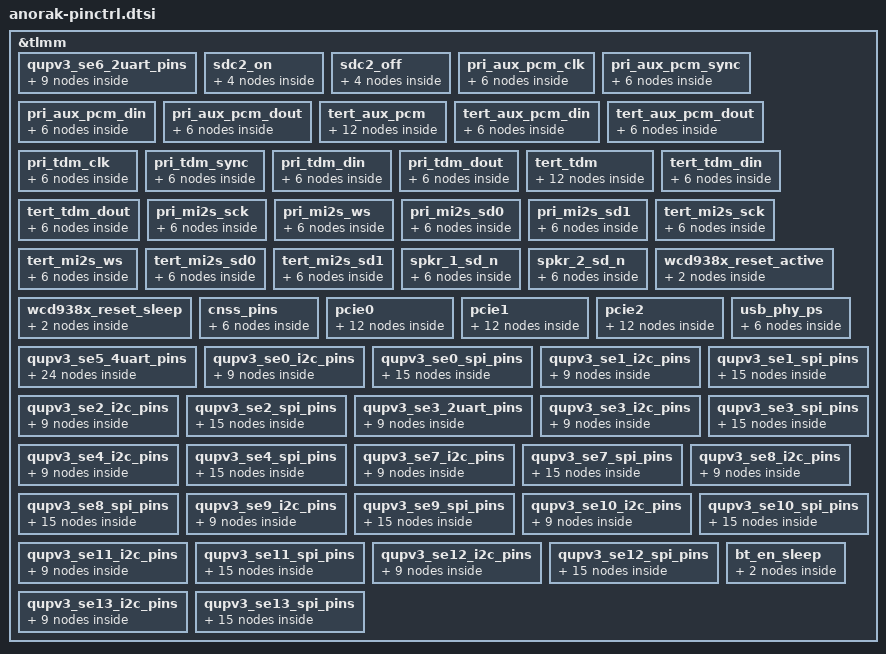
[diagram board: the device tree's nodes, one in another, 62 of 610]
&tlmm {

	qupv3_se6_2uart_pins: qupv3_se6_2uart_pins {
		qupv3_se6_2uart_tx_active: qupv3_se6_2uart_tx_active {
			mux {
				pins = "gpio156";
				function = "qup0_se6_l2";
			};

			config {
				pins = "gpio156";
				drive-strength = <2>;
				bias-disable;
			};
		};

		qupv3_se6_2uart_rx_active: qupv3_se6_2uart_rx_active {
			mux {
				pins = "gpio157";
				function = "qup0_se6_l3";
			};

			config {
				pins = "gpio157";
				drive-strength = <2>;
				bias-disable;
			};
		};

		qupv3_se6_2uart_sleep: qupv3_se6_2uart_sleep {
			mux {
				pins = "gpio156", "gpio157";
				function = "gpio";
			};

			config {
				pins = "gpio156", "gpio157";
				drive-strength = <2>;
				bias-pull-down;
			};
		};
	};

	sdc2_on: sdc2_on {
		clk {
			pins = "sdc2_clk";
			bias-disable;
			drive-strength = <16>;
		};

		cmd {
			pins = "sdc2_cmd";
			bias-pull-up;
			drive-strength = <10>;
		};

		data {
			pins = "sdc2_data";
			bias-pull-up;
			drive-strength = <10>;
		};

		sd-cd {
			pins = "gpio175";
			bias-pull-up;
			drive-strength = <2>;
		};
	};

	sdc2_off: sdc2_off {
		clk {
			pins = "sdc2_clk";
			bias-disable;
			drive-strength = <2>;
		};

		cmd {
			pins = "sdc2_cmd";
			bias-pull-up;
			drive-strength = <2>;
		};

		data {
			pins = "sdc2_data";
			bias-pull-up;
			drive-strength = <2>;
		};

		sd-cd {
			pins = "gpio175";
			bias-pull-up;
			drive-strength = <2>;
		};
	};

	pri_aux_pcm_clk {
		pri_aux_pcm_clk_sleep: pri_aux_pcm_clk_sleep {
			mux {
				pins = "gpio164";
				function = "gpio";
			};

			config {
				pins = "gpio164";
				drive-strength = <2>;   /* 2 mA */
				bias-pull-down;         /* PULL DOWN */
				input-enable;
			};
		};

		pri_aux_pcm_clk_active: pri_aux_pcm_clk_active {
			mux {
				pins = "gpio164";
				function = "i2s0_sck";
			};

			config {
				pins = "gpio164";
				drive-strength = <8>;   /* 8 mA */
				bias-disable;           /* NO PULL */
				output-high;
			};
		};
	};

	pri_aux_pcm_sync {
		pri_aux_pcm_sync_sleep: pri_aux_pcm_sync_sleep {
			mux {
				pins = "gpio166";
				function = "gpio";
			};

			config {
				pins = "gpio166";
				drive-strength = <2>;   /* 2 mA */
				bias-pull-down;         /* PULL DOWN */
				input-enable;
			};
		};

		pri_aux_pcm_sync_active: pri_aux_pcm_sync_active {
			mux {
				pins = "gpio166";
				function = "i2s0_ws";
			};

			config {
				pins = "gpio166";
				drive-strength = <8>;   /* 8 mA */
				bias-disable;           /* NO PULL */
				output-high;
			};
		};
	};

	pri_aux_pcm_din {
		pri_aux_pcm_din_sleep: pri_aux_pcm_din_sleep {
			mux {
				pins = "gpio163";
				function = "gpio";
			};

			config {
				pins = "gpio163";
				drive-strength = <2>;   /* 2 mA */
				bias-pull-down;         /* PULL DOWN */
				input-enable;
			};
		};

		pri_aux_pcm_din_active: pri_aux_pcm_din_active {
			mux {
				pins = "gpio163";
				function = "i2s0_data0";
			};

			config {
				pins = "gpio163";
				drive-strength = <8>;   /* 8 mA */
				bias-disable;           /* NO PULL */
			};
		};
	};

	pri_aux_pcm_dout {
		pri_aux_pcm_dout_sleep: pri_aux_pcm_dout_sleep {
			mux {
				pins = "gpio165";
				function = "gpio";
			};

			config {
				pins = "gpio165";
				drive-strength = <2>;   /* 2 mA */
				bias-pull-down;         /* PULL DOWN */
				input-enable;
			};
		};

		pri_aux_pcm_dout_active: pri_aux_pcm_dout_active {
			mux {
				pins = "gpio165";
				function = "i2s0_data1";
			};

			config {
				pins = "gpio165";
				drive-strength = <8>;   /* 8 mA */
				bias-disable;           /* NO PULL */
			};
		};
	};

	tert_aux_pcm {
		tert_aux_pcm_clk_sleep: tert_aux_pcm_clk_sleep {
			mux {
				pins = "gpio156";
				function = "gpio";
			};

			config {
				pins = "gpio156";
				drive-strength = <2>;   /* 2 mA */
				bias-pull-down;         /* PULL DOWN */
				input-enable;
			};
		};

		tert_aux_pcm_clk_active: tert_aux_pcm_clk_active {
			mux {
				pins = "gpio156";
				function = "i2s2_sck";
			};

			config {
				pins = "gpio156";
				drive-strength = <8>;   /* 8 mA */
				bias-disable;           /* NO PULL */
				output-high;
			};
		};

		tert_aux_pcm_ws_sleep: tert_aux_pcm_ws_sleep {
			mux {
				pins = "gpio157";
				function = "gpio";
			};

			config {
				pins = "gpio157";
				drive-strength = <2>;   /* 2 mA */
				bias-pull-down;         /* PULL DOWN */
				input-enable;
			};
		};

		tert_aux_pcm_ws_active: tert_aux_pcm_ws_active {
			mux {
				pins = "gpio157";
				function = "i2s2_ws";
			};

			config {
				pins = "gpio157";
				drive-strength = <8>;   /* 8 mA */
				bias-disable;           /* NO PULL */
				output-high;
			};
		};
	};

	tert_aux_pcm_din {
		tert_aux_pcm_din_sleep: tert_aux_pcm_din_sleep {
			mux {
				pins = "gpio155";
				function = "gpio";
			};

			config {
				pins = "gpio155";
				drive-strength = <2>;   /* 2 mA */
				bias-pull-down;         /* PULL DOWN */
				input-enable;
			};
		};

		tert_aux_pcm_din_active: tert_aux_pcm_din_active {
			mux {
				pins = "gpio155";
				function = "i2s2_data0";
			};

			config {
				pins = "gpio155";
				drive-strength = <8>;   /* 8 mA */
				bias-disable;           /* NO PULL */
			};
		};
	};

	tert_aux_pcm_dout {
		tert_aux_pcm_dout_sleep: tert_aux_pcm_dout_sleep {
			mux {
				pins = "gpio154";
				function = "gpio";
			};

			config {
				pins = "gpio154";
				drive-strength = <2>;   /* 2 mA */
				bias-pull-down;         /* PULL DOWN */
				input-enable;
			};
		};

		tert_aux_pcm_dout_active: tert_aux_pcm_dout_active {
			mux {
				pins = "gpio154";
				function = "i2s2_data1";
			};

			config {
				pins = "gpio154";
				drive-strength = <8>;   /* 8 mA */
				bias-disable;           /* NO PULL */
			};
		};
	};

	pri_tdm_clk {
		pri_tdm_clk_sleep: pri_tdm_clk_sleep {
			mux {
				pins = "gpio164";
				function = "gpio";
			};

			config {
				pins = "gpio164";
				drive-strength = <2>;   /* 2 mA */
				bias-pull-down;         /* PULL DOWN */
				input-enable;
			};
		};

		pri_tdm_clk_active: pri_tdm_clk_active {
			mux {
				pins = "gpio164";
				function = "i2s0_sck";
			};

			config {
				pins = "gpio164";
				drive-strength = <8>;   /* 8 mA */
				bias-disable;           /* NO PULL */
				output-high;
			};
		};
	};

	pri_tdm_sync {
		pri_tdm_sync_sleep: pri_tdm_sync_sleep {
			mux {
				pins = "gpio166";
				function = "gpio";
			};

			config {
				pins = "gpio166";
				drive-strength = <2>;   /* 2 mA */
				bias-pull-down;         /* PULL DOWN */
				input-enable;
			};
		};

		pri_tdm_sync_active: pri_tdm_sync_active {
			mux {
				pins = "gpio166";
				function = "i2s0_ws";
			};

			config {
				pins = "gpio166";
				drive-strength = <8>;   /* 8 mA */
				bias-disable;           /* NO PULL */
				output-high;
			};
		};
	};

	pri_tdm_din {
		pri_tdm_din_sleep: pri_tdm_din_sleep {
			mux {
				pins = "gpio163";
				function = "gpio";
			};

			config {
				pins = "gpio163";
				drive-strength = <2>;   /* 2 mA */
				bias-pull-down;         /* PULL DOWN */
				input-enable;
			};
		};

		pri_tdm_din_active: pri_tdm_din_active {
			mux {
				pins = "gpio163";
				function = "i2s0_data0";
			};

			config {
				pins = "gpio163";
				drive-strength = <8>;   /* 8 mA */
				bias-disable;           /* NO PULL */
			};
		};
	};

	pri_tdm_dout {
		pri_tdm_dout_sleep: pri_tdm_dout_sleep {
			mux {
				pins = "gpio165";
				function = "gpio";
			};

			config {
				pins = "gpio165";
				drive-strength = <2>;   /* 2 mA */
				bias-pull-down;         /* PULL DOWN */
				input-enable;
			};
		};

		pri_tdm_dout_active: pri_tdm_dout_active {
			mux {
				pins = "gpio165";
				function = "i2s0_data1";
			};

			config {
				pins = "gpio165";
				drive-strength = <8>;   /* 8 mA */
				bias-disable;           /* NO PULL */
			};
		};
	};

	tert_tdm {
		tert_tdm_clk_sleep: tert_tdm_clk_sleep {
			mux {
				pins = "gpio156";
				function = "gpio";
			};

			config {
				pins = "gpio156";
				drive-strength = <2>;   /* 2 mA */
				bias-pull-down;         /* PULL DOWN */
				input-enable;
			};
		};

		tert_tdm_clk_active: tert_tdm_clk_active {
			mux {
				pins = "gpio156";
				function = "i2s2_sck";
			};

			config {
				pins = "gpio156";
				drive-strength = <8>;   /* 8 mA */
				bias-disable;           /* NO PULL */
				output-high;
			};
		};

		tert_tdm_ws_sleep: tert_tdm_ws_sleep {
			mux {
				pins = "gpio157";
				function = "gpio";
			};

			config {
				pins = "gpio157";
				drive-strength = <2>;   /* 2 mA */
				bias-pull-down;         /* PULL DOWN */
				input-enable;
			};
		};

		tert_tdm_ws_active: tert_tdm_ws_active {
			mux {
				pins = "gpio157";
				function = "i2s2_ws";
			};

			config {
				pins = "gpio157";
				drive-strength = <8>;   /* 8 mA */
				bias-disable;           /* NO PULL */
				output-high;
			};
		};
	};

	tert_tdm_din {
		tert_tdm_din_sleep: tert_tdm_din_sleep {
			mux {
				pins = "gpio155";
				function = "gpio";
			};

			config {
				pins = "gpio155";
				drive-strength = <2>;   /* 2 mA */
				bias-pull-down;         /* PULL DOWN */
				input-enable;
			};
		};

		tert_tdm_din_active: tert_tdm_din_active {
			mux {
				pins = "gpio155";
				function = "i2s2_data0";
			};

			config {
				pins = "gpio155";
				drive-strength = <8>;   /* 8 mA */
				bias-disable;           /* NO PULL */
			};
		};
	};

	tert_tdm_dout {
		tert_tdm_dout_sleep: tert_tdm_dout_sleep {
			mux {
				pins = "gpio154";
				function = "gpio";
			};

			config {
				pins = "gpio154";
				drive-strength = <2>;   /* 2 mA */
				bias-pull-down;         /* PULL DOWN */
				input-enable;
			};
		};

		tert_tdm_dout_active: tert_tdm_dout_active {
			mux {
				pins = "gpio154";
				function = "i2s2_data1";
			};

			config {
				pins = "gpio154";
				drive-strength = <8>;   /* 8 mA */
				bias-disable;           /* NO PULL */
			};
		};
	};

	pri_mi2s_sck {
		pri_mi2s_sck_sleep: pri_mi2s_sck_sleep {
			mux {
				pins = "gpio164";
				function = "gpio";
			};

			config {
				pins = "gpio164";
				drive-strength = <2>;   /* 2 mA */
				bias-pull-down;         /* PULL DOWN */
				input-enable;
			};
		};

		pri_mi2s_sck_active: pri_mi2s_sck_active {
			mux {
				pins = "gpio164";
				function = "i2s0_sck";
			};

			config {
				pins = "gpio164";
				drive-strength = <8>;   /* 8 mA */
				bias-disable;           /* NO PULL */
				output-high;
			};
		};
	};

	pri_mi2s_ws {
		pri_mi2s_ws_sleep: pri_mi2s_ws_sleep {
			mux {
				pins = "gpio166";
				function = "gpio";
			};

			config {
				pins = "gpio166";
				drive-strength = <2>;   /* 2 mA */
				bias-pull-down;         /* PULL DOWN */
				input-enable;
			};
		};

		pri_mi2s_ws_active: pri_mi2s_ws_active {
			mux {
				pins = "gpio166";
				function = "i2s0_ws";
			};

			config {
				pins = "gpio166";
				drive-strength = <8>;   /* 8 mA */
				bias-disable;           /* NO PULL */
				output-high;
			};
		};
	};

	pri_mi2s_sd0 {
		pri_mi2s_sd0_sleep: pri_mi2s_sd0_sleep {
			mux {
				pins = "gpio163";
				function = "gpio";
			};

			config {
				pins = "gpio163";
				drive-strength = <2>;   /* 2 mA */
				bias-pull-down;         /* PULL DOWN */
				input-enable;
			};
		};

		pri_mi2s_sd0_active: pri_mi2s_sd0_active {
			mux {
				pins = "gpio163";
				function = "i2s0_data0";
			};

			config {
				pins = "gpio163";
				drive-strength = <8>;   /* 8 mA */
				bias-disable;           /* NO PULL */
				output-high;
			};
		};
	};

	pri_mi2s_sd1 {
		pri_mi2s_sd1_sleep: pri_mi2s_sd1_sleep {
			mux {
				pins = "gpio165";
				function = "gpio";
			};

			config {
				pins = "gpio165";
				drive-strength = <2>;   /* 2 mA */
				bias-pull-down;         /* PULL DOWN */
				input-enable;
			};
		};

		pri_mi2s_sd1_active: pri_mi2s_sd1_active {
			mux {
				pins = "gpio165";
				function = "i2s0_data1";
			};

			config {
				pins = "gpio165";
				drive-strength = <8>;   /* 8 mA */
				bias-disable;           /* NO PULL */
				output-high;
			};
		};
	};

	tert_mi2s_sck {
		tert_mi2s_sck_sleep: tert_mi2s_sck_sleep {
			mux {
				pins = "gpio156";
				function = "gpio";
			};

			config {
				pins = "gpio156";
				drive-strength = <2>;   /* 2 mA */
				bias-pull-down;         /* PULL DOWN */
				input-enable;
			};
		};

		tert_mi2s_sck_active: tert_mi2s_sck_active {
			mux {
				pins = "gpio156";
				function = "i2s2_sck";
			};

			config {
				pins = "gpio156";
				drive-strength = <8>;   /* 8 mA */
				bias-disable;           /* NO PULL */
			};
		};
	};

	tert_mi2s_ws {
		tert_mi2s_ws_sleep: tert_mi2s_ws_sleep {
			mux {
				pins = "gpio157";
				function = "gpio";
			};

			config {
				pins = "gpio157";
				drive-strength = <2>;   /* 2 mA */
				bias-pull-down;         /* PULL DOWN */
				input-enable;
			};
		};

		tert_mi2s_ws_active: tert_mi2s_ws_active {
			mux {
				pins = "gpio157";
				function = "i2s2_ws";
			};

			config {
				pins = "gpio157";
				drive-strength = <8>;   /* 8 mA */
				bias-disable;           /* NO PULL */
			};
		};
	};

	tert_mi2s_sd0 {
		tert_mi2s_sd0_sleep: tert_mi2s_sd0_sleep {
			mux {
				pins = "gpio155";
				function = "gpio";
			};

			config {
				pins = "gpio155";
				drive-strength = <2>;   /* 2 mA */
				bias-pull-down;         /* PULL DOWN */
				input-enable;
			};
		};

		tert_mi2s_sd0_active: tert_mi2s_sd0_active {
			mux {
				pins = "gpio155";
				function = "i2s2_data0";
			};

			config {
				pins = "gpio155";
				drive-strength = <8>;   /* 8 mA */
				bias-disable;           /* NO PULL */
			};
		};
	};

	tert_mi2s_sd1 {
		tert_mi2s_sd1_sleep: tert_mi2s_sd1_sleep {
			mux {
				pins = "gpio154";
				function = "gpio";
			};

			config {
				pins = "gpio154";
				drive-strength = <2>;   /* 2 mA */
				bias-pull-down;         /* PULL DOWN */
				input-enable;
			};
		};

		tert_mi2s_sd1_active: tert_mi2s_sd1_active {
			mux {
				pins = "gpio154";
				function = "i2s2_data1";
			};

			config {
				pins = "gpio154";
				drive-strength = <8>;   /* 8 mA */
				bias-disable;           /* NO PULL */
			};
		};
	};

	/* WSA speaker reset pins */
	spkr_1_sd_n {
		spkr_1_sd_n_sleep: spkr_1_sd_n_sleep {
			mux {
				pins = "gpio176";
				function = "gpio";
			};

			config {
				pins = "gpio176";
				drive-strength = <2>;   /* 2 mA */
				bias-pull-down;
				input-enable;
			};
		};

		spkr_1_sd_n_active: spkr_1_sd_n_active {
			mux {
				pins = "gpio176";
				function = "gpio";
			};

			config {
				pins = "gpio176";
				drive-strength = <16>;   /* 16 mA */
				bias-disable;
				output-high;
			};
		};
	};

	spkr_2_sd_n {
		spkr_2_sd_n_sleep: spkr_2_sd_n_sleep {
			mux {
				pins = "gpio177";
				function = "gpio";
			};

			config {
			pins = "gpio177";
			drive-strength = <2>;   /* 2 mA */
			bias-pull-down;
			input-enable;
			};
		};

		spkr_2_sd_n_active: spkr_2_sd_n_active {
			mux {
				pins = "gpio177";
				function = "gpio";
			};

			config {
				pins = "gpio177";
				drive-strength = <16>;   /* 16 mA */
				bias-disable;
				output-high;
			};
		};
	};

	/* WCD reset pin */
	wcd938x_reset_active: wcd938x_reset_active {
		mux {
			pins = "gpio180";
			function = "gpio";
		};

		config {
			pins = "gpio180";
			drive-strength = <16>;
			output-high;
		};
	};

	wcd938x_reset_sleep: wcd938x_reset_sleep {
		mux {
			pins = "gpio180";
			function = "gpio";
		};

		config {
			pins = "gpio180";
			drive-strength = <16>;
			bias-disable;
			output-low;
		};
	};
	cnss_pins: cnss_pins {
		cnss_wlan_en_active: cnss_wlan_en_active {
			mux {
				pins = "gpio120";
				function = "gpio";
			};

			config {
				pins = "gpio120";
				drive-strength = <16>;
				output-high;
				bias-pull-up;
			};
		};

		cnss_wlan_en_sleep: cnss_wlan_en_sleep {
			mux {
				pins = "gpio120";
				function = "gpio";
			};

			config {
				pins = "gpio120";
				drive-strength = <2>;
				output-low;
				bias-pull-down;
			};
		};
	};


	pcie0 {
		pcie0_perst_default: pcie0_perst_default {
			mux {
				pins = "gpio117";
				function = "gpio";
			};

			config {
				pins = "gpio117";
				drive-strength = <2>;
				bias-pull-down;
			};
		};

		pcie0_clkreq_default: pcie0_clkreq_default {
			mux {
				pins = "gpio118";
				function = "pcie0_clk_req";
			};

			config {
				pins = "gpio118";
				drive-strength = <2>;
				bias-pull-up;
			};
		};

		pcie0_wake_default: pcie0_wake_default {
			mux {
				pins = "gpio119";
				function = "gpio";
			};

			config {
				pins = "gpio119";
				drive-strength = <2>;
				bias-pull-up;
			};
		};

		pcie0_clkreq_sleep: pcie0_clkreq_sleep {
			mux {
				pins = "gpio118";
				function = "gpio";
			};

			config {
				pins = "gpio118";
				drive-strength = <2>;
				bias-pull-up;
			};
		};
	};

	pcie1 {
		pcie1_perst_default: pcie1_perst_default {
			mux {
				pins = "gpio141";
				function = "gpio";
			};

			config {
				pins = "gpio141";
				drive-strength = <2>;
				bias-pull-down;
			};
		};

		pcie1_clkreq_default: pcie1_clkreq_default {
			mux {
				pins = "gpio142";
				function = "pcie1_clk_req";
			};

			config {
				pins = "gpio142";
				drive-strength = <2>;
				bias-pull-up;
			};
		};

		pcie1_wake_default: pcie1_wake_default {
			mux {
				pins = "gpio143";
				function = "gpio";
			};

			config {
				pins = "gpio143";
				drive-strength = <2>;
				bias-pull-up;
			};
		};

		pcie1_clkreq_sleep: pcie1_clkreq_sleep {
			mux {
				pins = "gpio142";
				function = "gpio";
			};

			config {
				pins = "gpio142";
				drive-strength = <2>;
				bias-pull-up;
			};
		};
	};

	pcie2 {
		pcie2_perst_default: pcie2_perst_default {
			mux {
				pins = "gpio170";
				function = "gpio";
			};

			config {
				pins = "gpio170";
				drive-strength = <16>;
				bias-pull-down;
			};
		};

		pcie2_clkreq_default: pcie2_clkreq_default {
			mux {
				pins = "gpio171";
				function = "pcie2_clk_req";
			};

			config {
				pins = "gpio171";
				drive-strength = <2>;
				bias-pull-up;
			};
		};

		pcie2_wake_default: pcie2_wake_default {
			mux {
				pins = "gpio172";
				function = "gpio";
			};

			config {
				pins = "gpio172";
				drive-strength = <2>;
				bias-pull-up;
			};
		};

		pcie2_clkreq_sleep: pcie2_clkreq_sleep {
			mux {
				pins = "gpio171";
				function = "gpio";
			};

			config {
				pins = "gpio171";
				drive-strength = <2>;
				bias-pull-up;
			};
		};
	};

	usb_phy_ps: usb_phy_ps {
		usb3phy_portselect_default: usb3phy_portselect_default {
			mux {
				pins = "gpio160";
				function = "usb0_phy_ps";
			};

			config {
				pins = "gpio160";
				bias-disable;
				drive-strength = <2>;
			};
		};

		usb3phy_portselect_gpio: usb3phy_portselect_gpio {
			mux {
				pins = "gpio160";
				function = "gpio";
			};

			config {
				pins = "gpio160";
				drive-strength = <2>;
				bias-disable;
				input-enable;
			};
		};
	};

	qupv3_se5_4uart_pins: qupv3_se5_4uart_pins {
		qupv3_se5_default_cts: qupv3_se5_default_cts {
			mux {
				pins = "gpio126";
				function = "gpio";
			};

			config {
				pins = "gpio126";
				drive-strength = <2>;
				bias-disable;
			};
		};

		qupv3_se5_default_rts: qupv3_se5_default_rts {
			mux {
				pins = "gpio127";
				function = "gpio";
			};

			config {
				pins = "gpio127";
				drive-strength = <2>;
				bias-pull-down;
			};
		};

		qupv3_se5_default_tx: qupv3_se5_default_tx {
			mux {
				pins = "gpio128";
				function = "gpio";
			};

			config {
				pins = "gpio128";
				drive-strength = <2>;
				bias-pull-up;
			};
		};

		qupv3_se5_default_rx: qupv3_se5_default_rx {
			mux {
				pins = "gpio129";
				function = "gpio";
			};

			config {
				pins = "gpio129";
				drive-strength = <2>;
				bias-pull-down;
			};
		};

		qupv3_se5_cts: qupv3_se5_cts {
			mux {
				pins = "gpio126";
				function = "qup0_se5_l0";
			};

			config {
				pins = "gpio126";
				drive-strength = <2>;
				bias-disable;
			};
		};

		qupv3_se5_rts: qupv3_se5_rts {
			mux {
				pins = "gpio127";
				function = "qup0_se5_l1";
			};

			config {
				pins = "gpio127";
				drive-strength = <2>;
				bias-pull-down;
			};
		};

		qupv3_se5_tx: qupv3_se5_tx {
			mux {
				pins = "gpio128";
				function = "qup0_se5_l2";
			};

			config {
				pins = "gpio128";
				drive-strength = <2>;
				bias-pull-up;
			};
		};

		qupv3_se5_rx: qupv3_se5_rx {
			mux {
				pins = "gpio129";
				function = "qup0_se5_l3";
			};

			config {
				pins = "gpio129";
				drive-strength = <2>;
				bias-disable;
			};
		};
	};

	qupv3_se0_i2c_pins: qupv3_se0_i2c_pins {
		qupv3_se0_i2c_sda_active: qupv3_se0_i2c_sda_active {
			mux {
				pins = "gpio94";
				function = "qup0_se0_l0";
			};

			config {
				pins = "gpio94";
				drive-strength = <2>;
				bias-pull-up;
			};
		};

		qupv3_se0_i2c_scl_active: qupv3_se0_i2c_scl_active {
			mux {
				pins = "gpio95";
				function = "qup0_se0_l1";
			};

			config {
				pins = "gpio95";
				drive-strength = <2>;
				bias-pull-up;
			};
		};

		qupv3_se0_i2c_sleep: qupv3_se0_i2c_sleep {
			mux {
				pins = "gpio94", "gpio95";
				function = "gpio";
			};

			config {
				pins = "gpio94", "gpio95";
				drive-strength = <2>;
				bias-disable;
			};
		};
	};

	qupv3_se0_spi_pins: qupv3_se0_spi_pins {
		qupv3_se0_spi_miso_active: qupv3_se0_spi_miso_active {
			mux {
				pins = "gpio94";
				function = "qup0_se0_l0";
			};

			config {
				pins = "gpio94";
				drive-strength = <6>;
				bias-disable;
			};
		};

		qupv3_se0_spi_mosi_active: qupv3_se0_spi_mosi_active {
			mux {
				pins = "gpio95";
				function = "qup0_se0_l1";
			};

			config {
				pins = "gpio95";
				drive-strength = <6>;
				bias-disable;
			};
		};

		qupv3_se0_spi_clk_active: qupv3_se0_spi_clk_active {
			mux {
				pins = "gpio96";
				function = "qup0_se0_l2";
			};

			config {
				pins = "gpio96";
				drive-strength = <6>;
				bias-disable;
			};
		};

		qupv3_se0_spi_cs_active: qupv3_se0_spi_cs_active {
			mux {
				pins = "gpio97";
				function = "qup0_se0_l3";
			};

			config {
				pins = "gpio97";
				drive-strength = <6>;
				bias-disable;
			};
		};

		qupv3_se0_spi_sleep: qupv3_se0_spi_sleep {
			mux {
				pins = "gpio94", "gpio95",
					"gpio96", "gpio97";
				function = "gpio";
			};

			config {
				pins = "gpio94", "gpio95",
					"gpio96", "gpio97";
				drive-strength = <6>;
				bias-disable;
			};
		};
	};

	qupv3_se1_i2c_pins: qupv3_se1_i2c_pins {
		qupv3_se1_i2c_sda_active: qupv3_se1_i2c_sda_active {
			mux {
				pins = "gpio98";
				function = "qup0_se1_l0";
			};

			config {
				pins = "gpio98";
				drive-strength = <2>;
				bias-pull-up;
			};
		};

		qupv3_se1_i2c_scl_active: qupv3_se1_i2c_scl_active {
			mux {
				pins = "gpio99";
				function = "qup0_se1_l1";
			};

			config {
				pins = "gpio99";
				drive-strength = <2>;
				bias-pull-up;
			};
		};

		qupv3_se1_i2c_sleep: qupv3_se1_i2c_sleep {
			mux {
				pins = "gpio98", "gpio99";
				function = "gpio";
			};

			config {
				pins = "gpio98", "gpio99";
				drive-strength = <2>;
				bias-disable;
			};
		};
	};

	qupv3_se1_spi_pins: qupv3_se1_spi_pins {
		qupv3_se1_spi_miso_active: qupv3_se1_spi_miso_active {
			mux {
				pins = "gpio98";
				function = "qup0_se1_l0";
			};

			config {
				pins = "gpio98";
				drive-strength = <6>;
				bias-disable;
			};
		};

		qupv3_se1_spi_mosi_active: qupv3_se1_spi_mosi_active {
			mux {
				pins = "gpio99";
				function = "qup0_se1_l1";
			};

			config {
				pins = "gpio99";
				drive-strength = <6>;
				bias-disable;
			};
		};

		qupv3_se1_spi_clk_active: qupv3_se1_spi_clk_active {
			mux {
				pins = "gpio100";
				function = "qup0_se1_l2";
			};

			config {
				pins = "gpio100";
				drive-strength = <6>;
				bias-disable;
			};
		};

		qupv3_se1_spi_cs_active: qupv3_se1_spi_cs_active {
			mux {
				pins = "gpio101";
				function = "qup0_se1_l3";
			};

			config {
				pins = "gpio101";
				drive-strength = <6>;
				bias-disable;
			};
		};

		qupv3_se1_spi_sleep: qupv3_se1_spi_sleep {
			mux {
				pins = "gpio98", "gpio99",
					"gpio100", "gpio101";
				function = "gpio";
			};

			config {
				pins = "gpio98", "gpio99",
					"gpio100", "gpio101";
				drive-strength = <6>;
				bias-disable;
			};
		};
	};

	qupv3_se2_i2c_pins: qupv3_se2_i2c_pins {
		qupv3_se2_i2c_sda_active: qupv3_se2_i2c_sda_active {
			mux {
				pins = "gpio150";
				function = "qup0_se2_l0";
			};

			config {
				pins = "gpio150";
				drive-strength = <2>;
				bias-pull-up;
			};
		};

		qupv3_se2_i2c_scl_active: qupv3_se2_i2c_scl_active {
			mux {
				pins = "gpio151";
				function = "qup0_se2_l1";
			};

			config {
				pins = "gpio151";
				drive-strength = <2>;
				bias-pull-up;
			};
		};

		qupv3_se2_i2c_sleep: qupv3_se2_i2c_sleep {
			mux {
				pins = "gpio150", "gpio151";
				function = "gpio";
			};

			config {
				pins = "gpio150", "gpio151";
				drive-strength = <2>;
				bias-disable;
			};
		};
	};

	qupv3_se2_spi_pins: qupv3_se2_spi_pins {
		qupv3_se2_spi_miso_active: qupv3_se2_spi_miso_active {
			mux {
				pins = "gpio150";
				function = "qup0_se2_l0";
			};

			config {
				pins = "gpio150";
				drive-strength = <6>;
				bias-disable;
			};
		};

		qupv3_se2_spi_mosi_active: qupv3_se2_spi_mosi_active {
			mux {
				pins = "gpio151";
				function = "qup0_se2_l1";
			};

			config {
				pins = "gpio151";
				drive-strength = <6>;
				bias-disable;
			};
		};

		qupv3_se2_spi_clk_active: qupv3_se2_spi_clk_active {
			mux {
				pins = "gpio152";
				function = "qup0_se2_l2";
			};

			config {
				pins = "gpio152";
				drive-strength = <6>;
				bias-disable;
			};
		};

		qupv3_se2_spi_cs_active: qupv3_se2_spi_cs_active {
			mux {
				pins = "gpio153";
				function = "qup0_se2_l3";
			};

			config {
				pins = "gpio153";
				drive-strength = <6>;
				bias-disable;
			};
		};

		qupv3_se2_spi_sleep: qupv3_se2_spi_sleep {
			mux {
				pins = "gpio150", "gpio151",
					"gpio152", "gpio153";
				function = "gpio";
			};

			config {
				pins = "gpio150", "gpio151",
					"gpio152", "gpio153";
				drive-strength = <6>;
				bias-disable;
			};
		};
	};

	qupv3_se3_2uart_pins: qupv3_se3_2uart_pins {
		qupv3_se3_2uart_tx_active: qupv3_se3_2uart_tx_active {
			mux {
				pins = "gpio136";
				function = "qup0_se3_l2";
			};

			config {
				pins = "gpio136";
				drive-strength = <2>;
				bias-disable;
			};
		};

		qupv3_se3_2uart_rx_active: qupv3_se3_2uart_rx_active {
			mux {
				pins = "gpio137";
				function = "qup0_se3_l3";
			};

			config {
				pins = "gpio137";
				drive-strength = <2>;
				bias-disable;
			};
		};

		qupv3_se3_2uart_sleep: qupv3_se3_2uart_sleep {
			mux {
				pins = "gpio136", "gpio137";
				function = "gpio";
			};

			config {
				pins = "gpio136", "gpio137";
				drive-strength = <2>;
				bias-pull-down;
			};
		};
	};

	qupv3_se3_i2c_pins: qupv3_se3_i2c_pins {
		qupv3_se3_i2c_sda_active: qupv3_se3_i2c_sda_active {
			mux {
				pins = "gpio134";
				function = "qup0_se3_l0";
			};

			config {
				pins = "gpio134";
				drive-strength = <2>;
				bias-pull-up;
			};
		};

		qupv3_se3_i2c_scl_active: qupv3_se3_i2c_scl_active {
			mux {
				pins = "gpio135";
				function = "qup0_se3_l1";
			};

			config {
				pins = "gpio135";
				drive-strength = <2>;
				bias-pull-up;
			};
		};

		qupv3_se3_i2c_sleep: qupv3_se3_i2c_sleep {
			mux {
				pins = "gpio134", "gpio135";
				function = "gpio";
			};

			config {
				pins = "gpio134", "gpio135";
				drive-strength = <2>;
				bias-disable;
			};
		};
	};

	qupv3_se3_spi_pins: qupv3_se3_spi_pins {
		qupv3_se3_spi_miso_active: qupv3_se3_spi_miso_active {
			mux {
				pins = "gpio134";
				function = "qup0_se3_l0";
			};

			config {
				pins = "gpio134";
				drive-strength = <6>;
				bias-disable;
			};
		};

		qupv3_se3_spi_mosi_active: qupv3_se3_spi_mosi_active {
			mux {
				pins = "gpio135";
				function = "qup0_se3_l1";
			};

			config {
				pins = "gpio135";
				drive-strength = <6>;
				bias-disable;
			};
		};

		qupv3_se3_spi_clk_active: qupv3_se3_spi_clk_active {
			mux {
				pins = "gpio136";
				function = "qup0_se3_l2";
			};

			config {
				pins = "gpio136";
				drive-strength = <6>;
				bias-disable;
			};
		};

		qupv3_se3_spi_cs_active: qupv3_se3_spi_cs_active {
			mux {
				pins = "gpio137";
				function = "qup0_se3_l3";
			};

			config {
				pins = "gpio137";
				drive-strength = <6>;
				bias-disable;
			};
		};

		qupv3_se3_spi_sleep: qupv3_se3_spi_sleep {
			mux {
				pins = "gpio134", "gpio135",
					"gpio136", "gpio137";
				function = "gpio";
			};

			config {
				pins = "gpio134", "gpio135",
					"gpio136", "gpio137";
				drive-strength = <6>;
				bias-disable;
			};
		};
	};

	qupv3_se4_i2c_pins: qupv3_se4_i2c_pins {
		qupv3_se4_i2c_sda_active: qupv3_se4_i2c_sda_active {
			mux {
				pins = "gpio130";
				function = "qup0_se4_l0_mira";
			};

			config {
				pins = "gpio130";
				drive-strength = <2>;
				bias-pull-up;
			};
		};

		qupv3_se4_i2c_scl_active: qupv3_se4_i2c_scl_active {
			mux {
				pins = "gpio131";
				function = "qup0_se4_l1_mira";
			};

			config {
				pins = "gpio131";
				drive-strength = <2>;
				bias-pull-up;
			};
		};

		qupv3_se4_i2c_sleep: qupv3_se4_i2c_sleep {
			mux {
				pins = "gpio130", "gpio131";
				function = "gpio";
			};

			config {
				pins = "gpio130", "gpio131";
				drive-strength = <2>;
				bias-disable;
			};
		};
	};

	qupv3_se4_spi_pins: qupv3_se4_spi_pins {
		qupv3_se4_spi_miso_active: qupv3_se4_spi_miso_active {
			mux {
				pins = "gpio130";
				function = "qup0_se4_l0_mira";
			};

			config {
				pins = "gpio130";
				drive-strength = <6>;
				bias-disable;
			};
		};

		qupv3_se4_spi_mosi_active: qupv3_se4_spi_mosi_active {
			mux {
				pins = "gpio131";
				function = "qup0_se4_l1_mira";
			};

			config {
				pins = "gpio131";
				drive-strength = <6>;
				bias-disable;
			};
		};

		qupv3_se4_spi_clk_active: qupv3_se4_spi_clk_active {
			mux {
				pins = "gpio132";
				function = "qup0_se4_l2_mira";
			};

			config {
				pins = "gpio132";
				drive-strength = <6>;
				bias-disable;
			};
		};

		qupv3_se4_spi_cs_active: qupv3_se4_spi_cs_active {
			mux {
				pins = "gpio133";
				function = "qup0_se4_l3_mira";
			};

			config {
				pins = "gpio133";
				drive-strength = <6>;
				bias-disable;
			};
		};

		qupv3_se4_spi_sleep: qupv3_se4_spi_sleep {
			mux {
				pins = "gpio130", "gpio131",
					"gpio132", "gpio133";
				function = "gpio";
			};

			config {
				pins = "gpio130", "gpio131",
					"gpio132", "gpio133";
				drive-strength = <6>;
				bias-disable;
			};
		};
	};

	qupv3_se7_i2c_pins: qupv3_se7_i2c_pins {
		qupv3_se7_i2c_sda_active: qupv3_se7_i2c_sda_active {
			mux {
				pins = "gpio57";
				function = "qup1_se0_l0";
			};

			config {
				pins = "gpio57";
				drive-strength = <2>;
				bias-pull-up;
			};
		};

		qupv3_se7_i2c_scl_active: qupv3_se7_i2c_scl_active {
			mux {
				pins = "gpio58";
				function = "qup1_se0_l1";
			};

			config {
				pins = "gpio58";
				drive-strength = <2>;
				bias-pull-up;
			};
		};

		qupv3_se7_i2c_sleep: qupv3_se7_i2c_sleep {
			mux {
				pins = "gpio57", "gpio58";
				function = "gpio";
			};

			config {
				pins = "gpio57", "gpio58";
				drive-strength = <2>;
				bias-disable;
			};
		};
	};

	qupv3_se7_spi_pins: qupv3_se7_spi_pins {
		qupv3_se7_spi_miso_active: qupv3_se7_spi_miso_active {
			mux {
				pins = "gpio57";
				function = "qup1_se0_l0";
			};

			config {
				pins = "gpio57";
				drive-strength = <6>;
				bias-disable;
			};
		};

		qupv3_se7_spi_mosi_active: qupv3_se7_spi_mosi_active {
			mux {
				pins = "gpio58";
				function = "qup1_se0_l1";
			};

			config {
				pins = "gpio58";
				drive-strength = <6>;
				bias-disable;
			};
		};

		qupv3_se7_spi_clk_active: qupv3_se7_spi_clk_active {
			mux {
				pins = "gpio59";
				function = "qup1_se0_l2";
			};

			config {
				pins = "gpio59";
				drive-strength = <6>;
				bias-disable;
			};
		};

		qupv3_se7_spi_cs_active: qupv3_se7_spi_cs_active {
			mux {
				pins = "gpio60";
				function = "qup1_se0_l3_mira";
			};

			config {
				pins = "gpio60";
				drive-strength = <6>;
				bias-disable;
			};
		};

		qupv3_se7_spi_sleep: qupv3_se7_spi_sleep {
			mux {
				pins = "gpio57", "gpio58",
					"gpio59", "gpio60";
				function = "gpio";
			};

			config {
				pins = "gpio57", "gpio58",
					"gpio59", "gpio60";
				drive-strength = <6>;
				bias-disable;
			};
		};
	};

	qupv3_se8_i2c_pins: qupv3_se8_i2c_pins {
		qupv3_se8_i2c_sda_active: qupv3_se8_i2c_sda_active {
			mux {
				pins = "gpio63";
				function = "qup1_se1_l0";
			};

			config {
				pins = "gpio63";
				drive-strength = <2>;
				bias-pull-up;
			};
		};

		qupv3_se8_i2c_scl_active: qupv3_se8_i2c_scl_active {
			mux {
				pins = "gpio64";
				function = "qup1_se1_l1";
			};

			config {
				pins = "gpio64";
				drive-strength = <2>;
				bias-pull-up;
			};
		};

		qupv3_se8_i2c_sleep: qupv3_se8_i2c_sleep {
			mux {
				pins = "gpio63", "gpio64";
				function = "gpio";
			};

			config {
				pins = "gpio63", "gpio64";
				drive-strength = <2>;
				bias-disable;
			};
		};
	};

	qupv3_se8_spi_pins: qupv3_se8_spi_pins {
		qupv3_se8_spi_miso_active: qupv3_se8_spi_miso_active {
			mux {
				pins = "gpio63";
				function = "qup1_se1_l0";
			};

			config {
				pins = "gpio63";
				drive-strength = <6>;
				bias-disable;
			};
		};

		qupv3_se8_spi_mosi_active: qupv3_se8_spi_mosi_active {
			mux {
				pins = "gpio64";
				function = "qup1_se1_l1";
			};

			config {
				pins = "gpio64";
				drive-strength = <6>;
				bias-disable;
			};
		};

		qupv3_se8_spi_clk_active: qupv3_se8_spi_clk_active {
			mux {
				pins = "gpio65";
				function = "qup1_se1_l2";
			};

			config {
				pins = "gpio65";
				drive-strength = <6>;
				bias-disable;
			};
		};

		qupv3_se8_spi_cs_active: qupv3_se8_spi_cs_active {
			mux {
				pins = "gpio66";
				function = "qup1_se1_l3_mira";
			};

			config {
				pins = "gpio66";
				drive-strength = <6>;
				bias-disable;
			};
		};

		qupv3_se8_spi_sleep: qupv3_se8_spi_sleep {
			mux {
				pins = "gpio63", "gpio64",
					"gpio65", "gpio66";
				function = "gpio";
			};

			config {
				pins = "gpio63", "gpio64",
					"gpio65", "gpio66";
				drive-strength = <6>;
				bias-disable;
			};
		};
	};

	qupv3_se9_i2c_pins: qupv3_se9_i2c_pins {
		qupv3_se9_i2c_sda_active: qupv3_se9_i2c_sda_active {
			mux {
				pins = "gpio69";
				function = "qup1_se2_l0";
			};

			config {
				pins = "gpio69";
				drive-strength = <2>;
				bias-pull-up;
			};
		};

		qupv3_se9_i2c_scl_active: qupv3_se9_i2c_scl_active {
			mux {
				pins = "gpio70";
				function = "qup1_se2_l1";
			};

			config {
				pins = "gpio70";
				drive-strength = <2>;
				bias-pull-up;
			};
		};

		qupv3_se9_i2c_sleep: qupv3_se9_i2c_sleep {
			mux {
				pins = "gpio69", "gpio70";
				function = "gpio";
			};

			config {
				pins = "gpio69", "gpio70";
				drive-strength = <2>;
				bias-disable;
			};
		};
	};

	qupv3_se9_spi_pins: qupv3_se9_spi_pins {
		qupv3_se9_spi_miso_active: qupv3_se9_spi_miso_active {
			mux {
				pins = "gpio69";
				function = "qup1_se2_l0";
			};

			config {
				pins = "gpio69";
				drive-strength = <6>;
				bias-disable;
			};
		};

		qupv3_se9_spi_mosi_active: qupv3_se9_spi_mosi_active {
			mux {
				pins = "gpio70";
				function = "qup1_se2_l1";
			};

			config {
				pins = "gpio70";
				drive-strength = <6>;
				bias-disable;
			};
		};

		qupv3_se9_spi_clk_active: qupv3_se9_spi_clk_active {
			mux {
				pins = "gpio71";
				function = "qup1_se2_l2";
			};

			config {
				pins = "gpio71";
				drive-strength = <6>;
				bias-disable;
			};
		};

		qupv3_se9_spi_cs_active: qupv3_se9_spi_cs_active {
			mux {
				pins = "gpio72";
				function = "qup1_se2_l3_mira";
			};

			config {
				pins = "gpio72";
				drive-strength = <6>;
				bias-disable;
			};
		};

		qupv3_se9_spi_sleep: qupv3_se9_spi_sleep {
			mux {
				pins = "gpio69", "gpio70",
					"gpio71", "gpio72";
				function = "gpio";
			};

			config {
				pins = "gpio69", "gpio70",
					"gpio71", "gpio72";
				drive-strength = <6>;
				bias-disable;
			};
		};
	};

	qupv3_se10_i2c_pins: qupv3_se10_i2c_pins {
		qupv3_se10_i2c_sda_active: qupv3_se10_i2c_sda_active {
			mux {
				pins = "gpio75";
				function = "qup1_se3_l0";
			};

			config {
				pins = "gpio75";
				drive-strength = <2>;
				bias-pull-up;
			};
		};

		qupv3_se10_i2c_scl_active: qupv3_se10_i2c_scl_active {
			mux {
				pins = "gpio76";
				function = "qup1_se3_l1";
			};

			config {
				pins = "gpio76";
				drive-strength = <2>;
				bias-pull-up;
			};
		};

		qupv3_se10_i2c_sleep: qupv3_se10_i2c_sleep {
			mux {
				pins = "gpio75", "gpio76";
				function = "gpio";
			};

			config {
				pins = "gpio75", "gpio76";
				drive-strength = <2>;
				bias-disable;
			};
		};
	};

	qupv3_se10_spi_pins: qupv3_se10_spi_pins {
		qupv3_se10_spi_miso_active: qupv3_se10_spi_miso_active {
			mux {
				pins = "gpio75";
				function = "qup1_se3_l0";
			};

			config {
				pins = "gpio75";
				drive-strength = <6>;
				bias-disable;
			};
		};

		qupv3_se10_spi_mosi_active: qupv3_se10_spi_mosi_active {
			mux {
				pins = "gpio76";
				function = "qup1_se3_l1";
			};

			config {
				pins = "gpio76";
				drive-strength = <6>;
				bias-disable;
			};
		};

		qupv3_se10_spi_clk_active: qupv3_se10_spi_clk_active {
			mux {
				pins = "gpio77";
				function = "qup1_se3_l2";
			};

			config {
				pins = "gpio77";
				drive-strength = <6>;
				bias-disable;
			};
		};

		qupv3_se10_spi_cs_active: qupv3_se10_spi_cs_active {
			mux {
				pins = "gpio78";
				function = "qup1_se3_l3_mira";
			};

			config {
				pins = "gpio78";
				drive-strength = <6>;
				bias-disable;
			};
		};

		qupv3_se10_spi_sleep: qupv3_se10_spi_sleep {
			mux {
				pins = "gpio75", "gpio76",
					"gpio77", "gpio78";
				function = "gpio";
			};

			config {
				pins = "gpio75", "gpio76",
					"gpio77", "gpio78";
				drive-strength = <6>;
				bias-disable;
			};
		};
	};

	qupv3_se11_i2c_pins: qupv3_se11_i2c_pins {
		qupv3_se11_i2c_sda_active: qupv3_se11_i2c_sda_active {
			mux {
				pins = "gpio81";
				function = "qup1_se4_l0";
			};

			config {
				pins = "gpio81";
				drive-strength = <2>;
				bias-pull-up;
			};
		};

		qupv3_se11_i2c_scl_active: qupv3_se11_i2c_scl_active {
			mux {
				pins = "gpio82";
				function = "qup1_se4_l1";
			};

			config {
				pins = "gpio82";
				drive-strength = <2>;
				bias-pull-up;
			};
		};

		qupv3_se11_i2c_sleep: qupv3_se11_i2c_sleep {
			mux {
				pins = "gpio81", "gpio82";
				function = "gpio";
			};

			config {
				pins = "gpio81", "gpio82";
				drive-strength = <2>;
				bias-disable;
			};
		};
	};

	qupv3_se11_spi_pins: qupv3_se11_spi_pins {
		qupv3_se11_spi_miso_active: qupv3_se11_spi_miso_active {
			mux {
				pins = "gpio81";
				function = "qup1_se4_l0";
			};

			config {
				pins = "gpio81";
				drive-strength = <6>;
				bias-disable;
			};
		};

		qupv3_se11_spi_mosi_active: qupv3_se11_spi_mosi_active {
			mux {
				pins = "gpio82";
				function = "qup1_se4_l1";
			};

			config {
				pins = "gpio82";
				drive-strength = <6>;
				bias-disable;
			};
		};

		qupv3_se11_spi_clk_active: qupv3_se11_spi_clk_active {
			mux {
				pins = "gpio83";
				function = "qup1_se4_l2";
			};

			config {
				pins = "gpio83";
				drive-strength = <6>;
				bias-disable;
			};
		};

		qupv3_se11_spi_cs_active: qupv3_se11_spi_cs_active {
			mux {
				pins = "gpio84";
				function = "qup1_se4_l3";
			};

			config {
				pins = "gpio84";
				drive-strength = <6>;
				bias-disable;
			};
		};

		qupv3_se11_spi_sleep: qupv3_se11_spi_sleep {
			mux {
				pins = "gpio81", "gpio82",
					"gpio83", "gpio84";
				function = "gpio";
			};

			config {
				pins = "gpio81", "gpio82",
					"gpio83", "gpio84";
				drive-strength = <6>;
				bias-disable;
			};
		};
	};

	qupv3_se12_i2c_pins: qupv3_se12_i2c_pins {
		qupv3_se12_i2c_sda_active: qupv3_se12_i2c_sda_active {
			mux {
				pins = "gpio88";
				function = "qup1_se5_l0";
			};

			config {
				pins = "gpio88";
				drive-strength = <2>;
				bias-pull-up;
			};
		};

		qupv3_se12_i2c_scl_active: qupv3_se12_i2c_scl_active {
			mux {
				pins = "gpio89";
				function = "qup1_se5_l1";
			};

			config {
				pins = "gpio89";
				drive-strength = <2>;
				bias-pull-up;
			};
		};

		qupv3_se12_i2c_sleep: qupv3_se12_i2c_sleep {
			mux {
				pins = "gpio88", "gpio89";
				function = "gpio";
			};

			config {
				pins = "gpio88", "gpio89";
				drive-strength = <2>;
				bias-disable;
			};
		};
	};

	qupv3_se12_spi_pins: qupv3_se12_spi_pins {
		qupv3_se12_spi_miso_active: qupv3_se12_spi_miso_active {
			mux {
				pins = "gpio88";
				function = "qup1_se5_l0";
			};

			config {
				pins = "gpio88";
				drive-strength = <6>;
				bias-disable;
			};
		};

		qupv3_se12_spi_mosi_active: qupv3_se12_spi_mosi_active {
			mux {
				pins = "gpio89";
				function = "qup1_se5_l1";
			};

			config {
				pins = "gpio89";
				drive-strength = <6>;
				bias-disable;
			};
		};

		qupv3_se12_spi_clk_active: qupv3_se12_spi_clk_active {
			mux {
				pins = "gpio90";
				function = "qup1_se5_l2";
			};

			config {
				pins = "gpio90";
				drive-strength = <6>;
				bias-disable;
			};
		};

		qupv3_se12_spi_cs_active: qupv3_se12_spi_cs_active {
			mux {
				pins = "gpio91";
				function = "qup1_se5_l3";
			};

			config {
				pins = "gpio91";
				drive-strength = <6>;
				bias-disable;
			};
		};

		qupv3_se12_spi_sleep: qupv3_se12_spi_sleep {
			mux {
				pins = "gpio88", "gpio89",
					"gpio90", "gpio91";
				function = "gpio";
			};

			config {
				pins = "gpio88", "gpio89",
					"gpio90", "gpio91";
				drive-strength = <6>;
				bias-disable;
			};
		};
	};

	qupv3_se13_i2c_pins: qupv3_se13_i2c_pins {
		qupv3_se13_i2c_sda_active: qupv3_se13_i2c_sda_active {
			mux {
				pins = "gpio92";
				function = "qup1_se6_l0_mira";
			};

			config {
				pins = "gpio92";
				drive-strength = <2>;
				bias-pull-up;
			};
		};

		qupv3_se13_i2c_scl_active: qupv3_se13_i2c_scl_active {
			mux {
				pins = "gpio93";
				function = "qup1_se6_l1_mira";
			};

			config {
				pins = "gpio93";
				drive-strength = <2>;
				bias-pull-up;
			};
		};

		qupv3_se13_i2c_sleep: qupv3_se13_i2c_sleep {
			mux {
				pins = "gpio92", "gpio93";
				function = "gpio";
			};

			config {
				pins = "gpio92", "gpio93";
				drive-strength = <2>;
				bias-disable;
			};
		};
	};

	qupv3_se13_spi_pins: qupv3_se13_spi_pins {
		qupv3_se13_spi_miso_active: qupv3_se13_spi_miso_active {
			mux {
				pins = "gpio92";
				function = "qup1_se6_l0";
			};

			config {
				pins = "gpio92";
				drive-strength = <6>;
				bias-disable;
			};
		};

		qupv3_se13_spi_mosi_active: qupv3_se13_spi_mosi_active {
			mux {
				pins = "gpio93";
				function = "qup1_se6_l1";
			};

			config {
				pins = "gpio93";
				drive-strength = <6>;
				bias-disable;
			};
		};

		qupv3_se13_spi_clk_active: qupv3_se13_spi_clk_active {
			mux {
				pins = "gpio105";
				function = "qup1_se6_l2";
			};

			config {
				pins = "gpio105";
				drive-strength = <6>;
				bias-disable;
			};
		};

		qupv3_se13_spi_cs_active: qupv3_se13_spi_cs_active {
			mux {
				pins = "gpio106";
				function = "qup1_se6_l3";
			};

			config {
				pins = "gpio106";
				drive-strength = <6>;
				bias-disable;
			};
		};

		qupv3_se13_spi_sleep: qupv3_se13_spi_sleep {
			mux {
				pins = "gpio92", "gpio93",
					"gpio105", "gpio106";
				function = "gpio";
			};

			config {
				pins = "gpio92", "gpio93",
					"gpio105", "gpio106";
				drive-strength = <6>;
				bias-disable;
			};
		};
	};

	bt_en_sleep: bt_en_sleep {
		mux {
			pins = "gpio122";
			function = "gpio";
		};

		config {
			pins = "gpio122";
			drive-strength = <2>;
			output-low;
			bias-pull-down;
		};
	};
};
